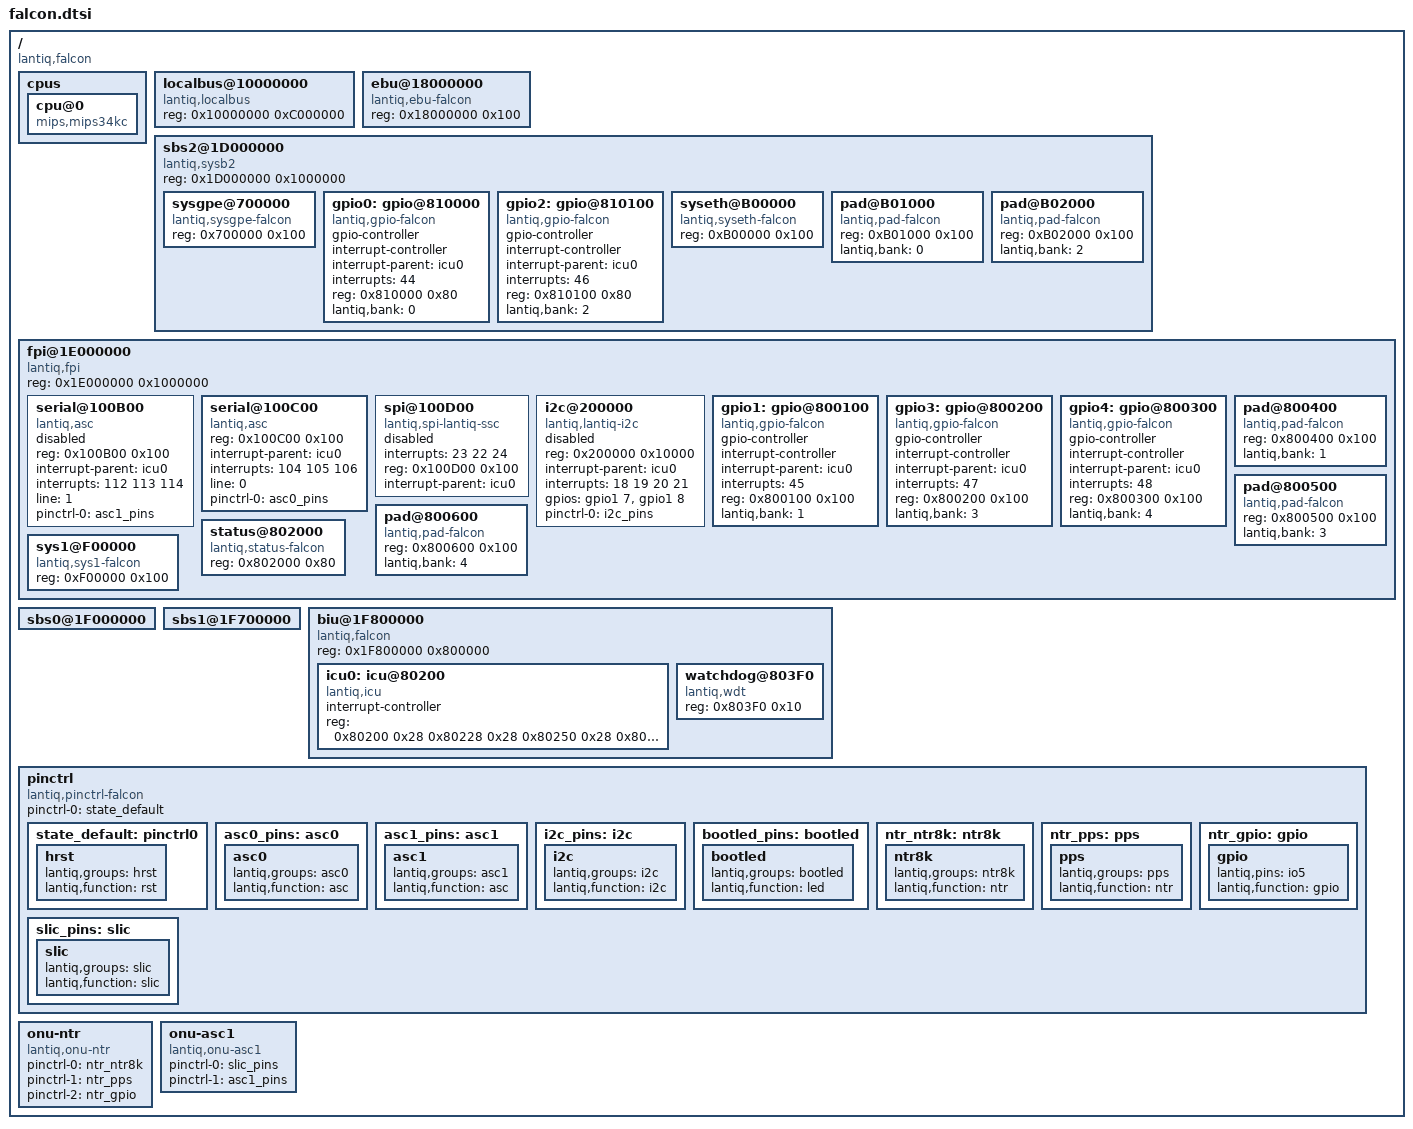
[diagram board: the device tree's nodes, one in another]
/ {
	#address-cells = <1>;
	#size-cells = <1>;
	compatible = "lantiq,falcon";

	cpus {
		cpu@0 {
			compatible = "mips,mips34kc";
		};
	};

	localbus@10000000 {
		#address-cells = <1>;
		#size-cells = <1>;
		compatible = "lantiq,localbus", "simple-bus";
		reg = <0x10000000 0xC000000>;
		ranges = <0x0 0x10000000 0xC000000>;
	};

	ebu@18000000 {
		compatible = "lantiq,ebu-falcon";
		reg = <0x18000000 0x100>;
	};

	sbs2@1D000000 {
		#address-cells = <1>;
		#size-cells = <1>;
		compatible = "lantiq,sysb2", "simple-bus";
		reg = <0x1D000000 0x1000000>;
		ranges = <0x0 0x1D000000 0x1000000>;

		sysgpe@700000 {
			compatible = "lantiq,sysgpe-falcon";
			reg = <0x700000 0x100>;
		};

		gpio0: gpio@810000 {
			compatible = "lantiq,gpio-falcon";
			gpio-controller;
			#gpio-cells = <2>;
			interrupt-controller;
			#interrupt-cells = <2>;
			interrupt-parent = <&icu0>;
			interrupts = <44>;
			reg = <0x810000 0x80>;
			lantiq,bank = <0>;
		};

		gpio2: gpio@810100 {
			compatible = "lantiq,gpio-falcon";
			gpio-controller;
			#gpio-cells = <2>;
			interrupt-controller;
			#interrupt-cells = <2>;
			interrupt-parent = <&icu0>;
			interrupts = <46>;
			reg = <0x810100 0x80>;
			lantiq,bank = <2>;
		};

		syseth@B00000 {
			compatible = "lantiq,syseth-falcon";
			reg = <0xB00000 0x100>;
		};

		pad@B01000 {
			compatible = "lantiq,pad-falcon";
			reg = <0xB01000 0x100>;
			lantiq,bank = <0>;
		};

		pad@B02000 {
			compatible = "lantiq,pad-falcon";
			reg = <0xB02000 0x100>;
			lantiq,bank = <2>;
		};
	};

	fpi@1E000000 {
		#address-cells = <1>;
		#size-cells = <1>;
		compatible = "lantiq,fpi", "simple-bus";
		reg = <0x1E000000 0x1000000>;
		ranges = <0x0 0x1E000000 0x1000000>;

		serial@100B00 {
			status = "disabled";
			compatible = "lantiq,asc";
			reg = <0x100B00 0x100>;
			interrupt-parent = <&icu0>;
			interrupts = <112 113 114>;
			line = <1>;
			pinctrl-names = "default";
			pinctrl-0 = <&asc1_pins>;
		};

		serial@100C00 {
			compatible = "lantiq,asc";
			reg = <0x100C00 0x100>;
			interrupt-parent = <&icu0>;
			interrupts = <104 105 106>;
			line = <0>;
			pinctrl-names = "default";
			pinctrl-0 = <&asc0_pins>;
		};

		spi@100D00 {
			status = "disabled";
			compatible = "lantiq,spi-lantiq-ssc";
			interrupts = <23 22 24>;
			#address-cells = <1>;
			#size-cells = <0>;
			reg = <0x100D00 0x100>;
			interrupt-parent = <&icu0>;
		};

		i2c@200000 {
			status = "disabled";
			compatible = "lantiq,lantiq-i2c";
			reg = <0x200000 0x10000>;
			interrupt-parent = <&icu0>;
			interrupts = <18 19 20 21>;
			gpios = <&gpio1 7 0 &gpio1 8 0>;
			pinctrl-names = "default";
			pinctrl-0 = <&i2c_pins>;
		};

		gpio1: gpio@800100 {
			compatible = "lantiq,gpio-falcon";
			gpio-controller;
			#gpio-cells = <2>;
			interrupt-controller;
			#interrupt-cells = <2>;
			interrupt-parent = <&icu0>;
			interrupts = <45>;
			reg = <0x800100 0x100>;
			lantiq,bank = <1>;
		};

		gpio3: gpio@800200 {
			compatible = "lantiq,gpio-falcon";
			gpio-controller;
			#gpio-cells = <2>;
			interrupt-controller;
			#interrupt-cells = <2>;
			interrupt-parent = <&icu0>;
			interrupts = <47>;
			reg = <0x800200 0x100>;
			lantiq,bank = <3>;
		};

		gpio4: gpio@800300 {
			compatible = "lantiq,gpio-falcon";
			gpio-controller;
			#gpio-cells = <2>;
			interrupt-controller;
			#interrupt-cells = <2>;
			interrupt-parent = <&icu0>;
			interrupts = <48>;
			reg = <0x800300 0x100>;
			lantiq,bank = <4>;
		};

		pad@800400 {
			compatible = "lantiq,pad-falcon";
			reg = <0x800400 0x100>;
			lantiq,bank = <1>;
		};

		pad@800500 {
			compatible = "lantiq,pad-falcon";
			reg = <0x800500 0x100>;
			lantiq,bank = <3>;
		};

		pad@800600 {
			compatible = "lantiq,pad-falcon";
			reg = <0x800600 0x100>;
			lantiq,bank = <4>;
		};

		status@802000 {
			compatible = "lantiq,status-falcon";
			reg = <0x802000 0x80>;
		};

		sys1@F00000 {
			compatible = "lantiq,sys1-falcon";
			reg = <0xF00000 0x100>;
		};

	};

	sbs0@1F000000 {

	};

	sbs1@1F700000 {

	};

	biu@1F800000 {
		#address-cells = <1>;
		#size-cells = <1>;
		compatible = "lantiq,falcon";
		reg = <0x1F800000 0x800000>;
		ranges = <0x0 0x1F800000 0x7FFFFF>;

		icu0: icu@80200 {
			#interrupt-cells = <1>;
			interrupt-controller;
			compatible = "lantiq,icu";
			reg = <0x80200 0x28
				0x80228 0x28
				0x80250 0x28
				0x80278 0x28
				0x802a0 0x28>;
		};

		watchdog@803F0 {
			compatible = "lantiq,wdt";
			reg = <0x803F0 0x10>;
		};
	};

	pinctrl {
		compatible = "lantiq,pinctrl-falcon";
		pinctrl-names = "default";
		pinctrl-0 = <&state_default>;

		state_default: pinctrl0 {
			/*ntr {
				lantiq,groups = "ntr8k";
				lantiq,function = "ntr";
			};*/
			hrst {
				lantiq,groups = "hrst";
				lantiq,function = "rst";
			};
		};

		asc0_pins: asc0 {
			asc0 {
				lantiq,groups = "asc0";
				lantiq,function = "asc";
			};
		};
		asc1_pins: asc1 {
			asc1 {
				lantiq,groups = "asc1";
				lantiq,function = "asc";
			};
		};
		i2c_pins: i2c {
			i2c {
				lantiq,groups = "i2c";
				lantiq,function = "i2c";
			};
		};
		bootled_pins: bootled {
			bootled {
				lantiq,groups = "bootled";
				lantiq,function = "led";
			};
		};
		ntr_ntr8k: ntr8k {
			ntr8k {
				lantiq,groups = "ntr8k";
				lantiq,function = "ntr";
			};
		};
		ntr_pps: pps {
			pps {
				lantiq,groups = "pps";
				lantiq,function = "ntr";
			};
		};
		ntr_gpio: gpio {
			gpio {
				lantiq,pins = "io5";
				lantiq,function = "gpio";
			};
		};
		slic_pins: slic {
			slic {
				lantiq,groups = "slic";
				lantiq,function = "slic";
			};
		};
	};

	onu-ntr {
		compatible = "lantiq,onu-ntr";
		pinctrl-names = "ntr8k", "pps", "gpio";
		pinctrl-0 = <&ntr_ntr8k>;
		pinctrl-1 = <&ntr_pps>;
		pinctrl-2 = <&ntr_gpio>;
	};

	onu-asc1 {
		compatible = "lantiq,onu-asc1";
		pinctrl-names = "default", "asc1";
		pinctrl-0 = <&slic_pins>;
		pinctrl-1 = <&asc1_pins>;
	};

};
